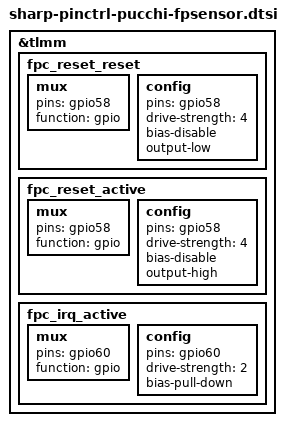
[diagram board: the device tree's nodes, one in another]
/* Copyright (c) 2016-2017, The Linux Foundation. All rights reserved.
 *
 * This program is free software; you can redistribute it and/or modify
 * it under the terms of the GNU General Public License version 2 and
 * only version 2 as published by the Free Software Foundation.
 *
 * This program is distributed in the hope that it will be useful,
 * but WITHOUT ANY WARRANTY; without even the implied warranty of
 * MERCHANTABILITY or FITNESS FOR A PARTICULAR PURPOSE.  See the
 * GNU General Public License for more details.
 */

&tlmm {
	/*****************************************/
	/*  pinctrl customize setting            */
	/*****************************************/

	fpc_reset_reset: fpc_reset_reset {
		mux {
			pins = "gpio58";
			function = "gpio";
		};
		config {
			pins = "gpio58";
			drive-strength = <4>;
			bias-disable;
			output-low;
		};
	};
	fpc_reset_active: fpc_reset_active {
		mux {
			pins = "gpio58";
			function = "gpio";
		};
		config {
			pins = "gpio58";
			drive-strength = <4>;
			bias-disable;
			output-high;
		};
	};

	fpc_irq_active: fpc_irq_active {
		mux {
			pins = "gpio60";
			function = "gpio";
		};
		config {
			pins = "gpio60";
			drive-strength = <2>;
			bias-pull-down;
		};
	};

};

